# PIC32CX5109BZ31048 device description
Architecture: CORTEX-M4; Family: PIC32CX; Series: PIC32CXBZ31
Registers are 32-bit, read-write, reset 0x0 unless marked. A register's access mark holds for its fields unless they carry their own. Offsets are from the block's base; [hi:lo] are bit positions; lines under a group give offsets from that group; {n}, {i} and the like mark numbered series.

## EVSYS — Event System Interface
Instances: EVSYS 0x41006000
0x00 CTRLA 8-bit — Control
  [0] SWRST — Software Reset
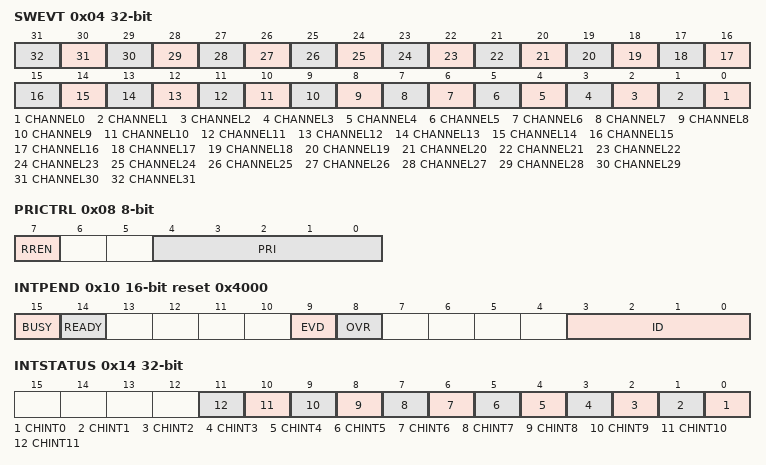
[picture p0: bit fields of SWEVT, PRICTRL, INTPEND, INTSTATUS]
0x04 SWEVT wo — Software Event
  [n] CHANNEL{n} (n=0..31) — Channel {n} Software Selection
0x08 PRICTRL 8-bit — Priority Control
  [7] RREN — Round-Robin Scheduling Enable
  [4:0] PRI — Channel Priority Number
0x10 INTPEND 16-bit reset 0x4000 — Channel Pending Interrupt
  [15] BUSY
  [14] READY
  [9] EVD — Channel Event Detected
  [8] OVR — Channel Overrun
  [3:0] ID — Channel ID
0x14 INTSTATUS ro — Interrupt Status
  [n] CHINT{n} (n=0..11) — Channel {n} Pending Interrupt
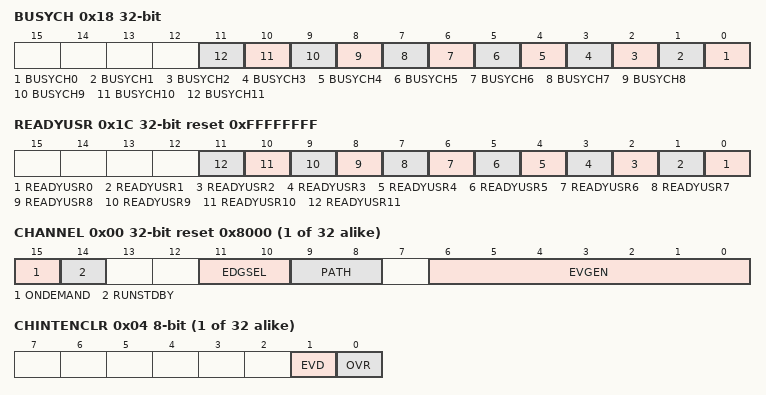
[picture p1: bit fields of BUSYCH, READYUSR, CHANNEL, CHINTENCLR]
0x18 BUSYCH ro — Busy Channels
  [n] BUSYCH{n} (n=0..11) — Busy Channel {n}
0x1C READYUSR ro reset 0xFFFFFFFF — Ready Users
  [n] READYUSR{n} (n=0..11) — Ready User for Channel {n}
{0x20+8i} CHANNEL[{i}] (i=0..31) group
  0x00 CHANNEL reset 0x8000 — Channel n Control
    [15] ONDEMAND — Generic Clock On Demand
    [14] RUNSTDBY — Run in standby
    [11:10] EDGSEL — Edge Detection Selection
      0=NO_EVT_OUTPUT (No event output when using the resynchronized or synchronous path); 1=RISING_EDGE (Event detection only on the rising edge of the signal from the event generator when using the resynchronized or synchronous path); 2=FALLING_EDGE (Event detection only on the falling edge of the signal from the event generator when using the resynchronized or synchronous path); 3=BOTH_EDGES (Event detection on rising and falling edges of the signal from the event generator when using the resynchronized or synchronous path)
    [9:8] PATH — Path Selection
      0=SYNCHRONOUS (Synchronous path); 1=RESYNCHRONIZED (Resynchronized path); 2=ASYNCHRONOUS (Asynchronous path)
    [6:0] EVGEN — Event Generator Selection
  0x04 CHINTENCLR 8-bit (atomic clear) — Channel n Interrupt Enable Clear
    [1] EVD — Channel Event Detected Interrupt Disable
    [0] OVR — Channel Overrun Interrupt Disable
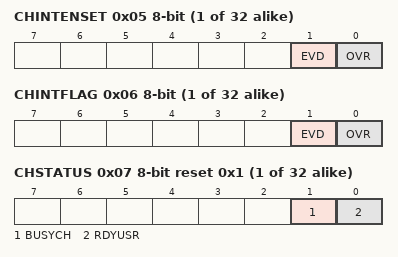
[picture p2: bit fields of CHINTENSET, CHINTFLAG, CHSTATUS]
  0x05 CHINTENSET 8-bit (atomic set) — Channel n Interrupt Enable Set
    [1] EVD — Channel Event Detected Interrupt Enable
    [0] OVR — Channel Overrun Interrupt Enable
  0x06 CHINTFLAG 8-bit (atomic clear) — Channel n Interrupt Flag Status and Clear
    [1] EVD — Channel Event Detected
    [0] OVR — Channel Overrun
  0x07 CHSTATUS 8-bit ro reset 0x1 — Channel n Status
    [1] BUSYCH — Busy Channel
    [0] RDYUSR — Ready User
{0x120+4i} USER[{i}] (i=0..56) — User Multiplexer n
  [5:0] CHANNEL — Channel Event Selection

## NVM — flash controller
Instances: NVM 0x44000600
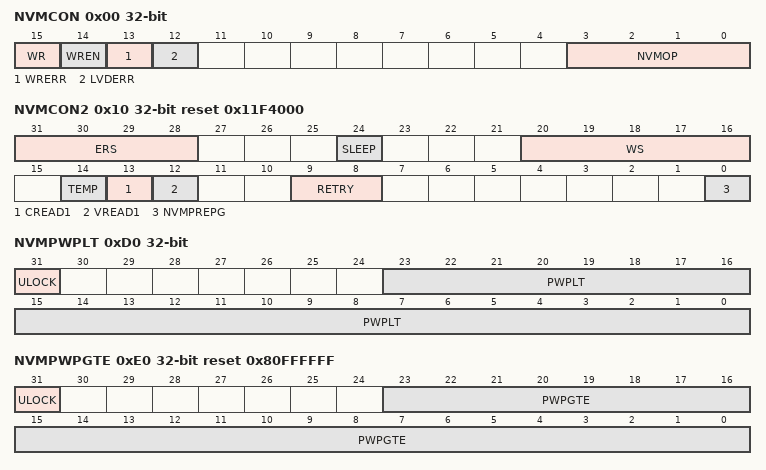
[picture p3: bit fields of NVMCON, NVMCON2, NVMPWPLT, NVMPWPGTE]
0x00 NVMCON
  [15] WR, [14] WREN, [13] WRERR, [12] LVDERR, [3:0] NVMOP
0x04 NVMCONCLR
0x08 NVMCONSET
0x0C NVMCONINV
0x10 NVMCON2 reset 0x11F4000
  [31:28] ERS, [24] SLEEP, [20:16] WS, [14] TEMP, [13] CREAD1, [12] VREAD1, [9:8] RETRY, [0] NVMPREPG
0x14 NVMCON2CLR
0x18 NVMCON2SET
0x1C NVMCON2INV
0x20 NVMKEY
0x30 NVMADDR
{0x40+0x10*i} NVMDATA{i} (i=0..3)
0xC0 NVMSRCADDR
0xD0 NVMPWPLT
  [31] ULOCK, [23:0] PWPLT
0xD4 NVMPWPLTCLR
0xD8 NVMPWPLTSET
0xDC NVMPWPLTINV
0xE0 NVMPWPGTE reset 0x80FFFFFF
  [31] ULOCK, [23:0] PWPGTE
0xE4 NVMPWPGTECLR
0xE8 NVMPWPGTESET
0xEC NVMPWPGTEINV
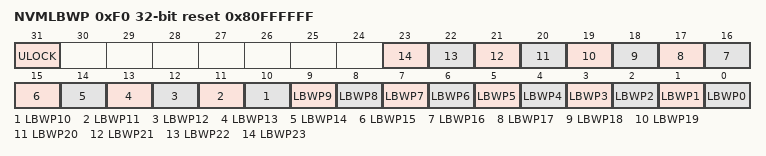
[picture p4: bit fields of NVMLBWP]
0xF0 NVMLBWP reset 0x80FFFFFF
  [31] ULOCK, [n] LBWP{n} (n=0..23)
0xF4 NVMLBWPCLR
0xF8 NVMLBWPSET
0xFC NVMLBWPINV

## FREQM — Frequency Meter
Instances: FREQM 0x40000400
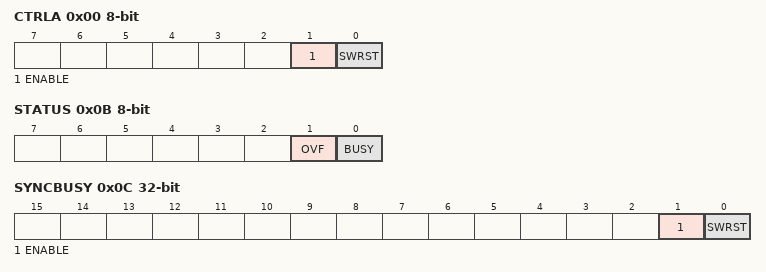
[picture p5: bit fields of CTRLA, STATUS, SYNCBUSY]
0x00 CTRLA 8-bit — Control A Register
  [1] ENABLE
  [0] SWRST — Software Reset
0x01 CTRLB 8-bit wo — Control B Register
  [0] START — Start Measurement
0x02 CFGA 16-bit — Config A register
  [7:0] REFNUM — Number of Reference Clock Cycles
0x08 INTENCLR 8-bit (atomic clear) — Interrupt Enable Clear Register
  [0] DONE — Measurement Done Interrupt Enable
0x09 INTENSET 8-bit (atomic set) — Interrupt Enable Set Register
  [0] DONE — Measurement Done Interrupt Enable
0x0A INTFLAG 8-bit (atomic clear) — Interrupt Flag Register
  [0] DONE — Measurement Done
0x0B STATUS 8-bit
  [1] OVF — Sticky Count Value Overflow
  [0] BUSY — FREQM Status
0x0C SYNCBUSY ro — Synchronization Busy Register
  [1] ENABLE
  [0] SWRST — Software Reset
0x10 VALUE ro — Count Value Register
  [23:0] VALUE — Measurement Value
